# sce register map
Vendor: cramium
Cramium SoC, product name TBD
Registers are 32-bit, read-write, reset 0x0 unless marked. A register's access mark holds for its fields unless they carry their own. Offsets are from the block's base; lines under a group give offsets from that group; [hi:lo] are bit positions; {n}, {i} and the like mark numbered series; 'fields as' and 'values as' point back to an identical list; <NAME> marks a mode.

## Memory map
0x40028000 SCE_GLBSFR size 0x58
0x40029000 SCEDMA size 0x64
0x4002B000 COMBOHASH size 0x3C
0x4002C000 PKE size 0x44
0x4002D000 AES size 0x40
0x4002E000 TRNG size 0x4
0x4002F000 ALU size 0x4

## Further device data
memoryRegions:
  SCE baseAddress=0x40028000 size=0x00008000

## AES
Base 0x4002D000
0x00 SFR_CRFUNC
  [7:0] sfr_crfunc — sfr_crfunc read/write control register
0x04 SFR_AR
  [31:0] sfr_ar — sfr_ar performs action on write of value: 0x5a
0x08 SFR_SRMFSM
  [7:0] sfr_srmfsm — sfr_srmfsm read only status register
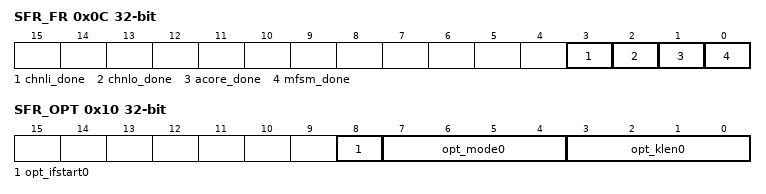
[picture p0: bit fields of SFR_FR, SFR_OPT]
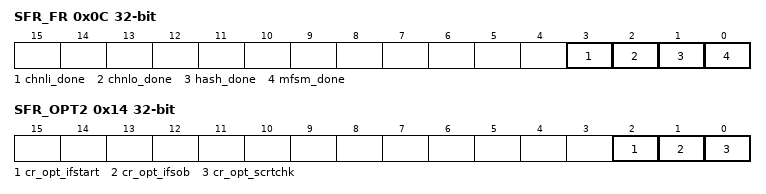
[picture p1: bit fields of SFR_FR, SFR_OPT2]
0x0C SFR_FR
  [3] chnli_done — sfr_srmfsm flag register. `1` means event happened, write back `1` in respective bit position to clear the flag
  [2] chnlo_done — sfr_srmfsm flag register. `1` means event happened, write back `1` in respective bit position to clear the flag
  [1] acore_done — sfr_srmfsm flag register. `1` means event happened, write back `1` in respective bit position to clear the flag
  [0] mfsm_done — sfr_srmfsm flag register. `1` means event happened, write back `1` in respective bit position to clear the flag
0x10 SFR_OPT
  [8] opt_ifstart0 — sfr_crfunc read/write control register
  [7:4] opt_mode0 — sfr_crfunc read/write control register
  [3:0] opt_klen0 — sfr_crfunc read/write control register
0x14 SFR_OPT1
  [15:0] sfr_opt1 — sfr_opt1 read/write control register
0x30 SFR_SEGPTR_PTRID_IV
  [11:0] PTRID_IV — cr_segptrstart read/write control register
0x34 SFR_SEGPTR_PTRID_AKEY
  [11:0] PTRID_AKEY — cr_segptrstart read/write control register
0x38 SFR_SEGPTR_PTRID_AIB
  [11:0] PTRID_AIB — cr_segptrstart read/write control register
0x3C SFR_SEGPTR_PTRID_AOB
  [11:0] PTRID_AOB — cr_segptrstart read/write control register

## COMBOHASH
Base 0x4002B000
0x00 SFR_CRFUNC
  [7:0] cr_func — cr_func read/write control register
0x04 SFR_AR
  [31:0] sfr_ar — sfr_ar performs action on write of value: 0x5a
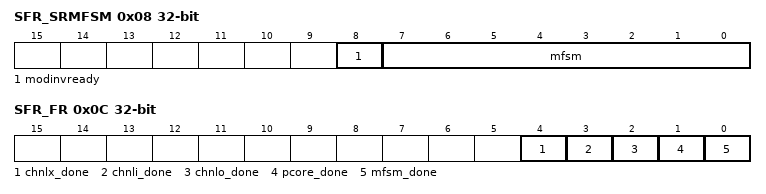
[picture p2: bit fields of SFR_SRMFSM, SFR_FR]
0x08 SFR_SRMFSM
  [7:0] mfsm — mfsm read only status register
0x0C SFR_FR
  [3] chnli_done — mfsm flag register. `1` means event happened, write back `1` in respective bit position to clear the flag
  [2] chnlo_done — mfsm flag register. `1` means event happened, write back `1` in respective bit position to clear the flag
  [1] hash_done — mfsm flag register. `1` means event happened, write back `1` in respective bit position to clear the flag
  [0] mfsm_done — mfsm flag register. `1` means event happened, write back `1` in respective bit position to clear the flag
0x10 SFR_OPT1
  [15:0] cr_opt_hashcnt — cr_opt_hashcnt read/write control register
0x14 SFR_OPT2
  [2] cr_opt_ifstart — cr_opt_hashcnt read/write control register
  [1] cr_opt_ifsob — cr_opt_hashcnt read/write control register
  [0] cr_opt_scrtchk — cr_opt_hashcnt read/write control register
0x20 SFR_SEGPTR_SEGID_LKEY
  [11:0] SEGID_LKEY — cr_segptrstart read/write control register
0x24 SFR_SEGPTR_SEGID_KEY
  [11:0] SEGID_KEY — cr_segptrstart read/write control register
0x2C SFR_SEGPTR_SEGID_SCRT
  [11:0] SEGID_SCRT — cr_segptrstart read/write control register
0x30 SFR_SEGPTR_SEGID_MSG
  [11:0] SEGID_MSG — cr_segptrstart read/write control register
0x34 SFR_SEGPTR_SEGID_HOUT
  [11:0] SEGID_HOUT — cr_segptrstart read/write control register
0x38 SFR_SEGPTR_SEGID_SOB
  [11:0] SEGID_SOB — cr_segptrstart read/write control register

## PKE
Base 0x4002C000
0x00 SFR_CRFUNC
  [7:0] sfr_crfunc — sfr_crfunc read/write control register
0x04 SFR_AR
  [31:0] sfr_ar — sfr_ar performs action on write of value: 0x5a
0x08 SFR_SRMFSM
  [8] modinvready — cr_segptrstart read only status register
  [7:0] mfsm — cr_segptrstart read only status register
0x0C SFR_FR
  [4] chnlx_done — cr_segptrstart flag register. `1` means event happened, write back `1` in respective bit position to clear the flag
  [3] chnli_done — cr_segptrstart flag register. `1` means event happened, write back `1` in respective bit position to clear the flag
  [2] chnlo_done — cr_segptrstart flag register. `1` means event happened, write back `1` in respective bit position to clear the flag
  [1] pcore_done — cr_segptrstart flag register. `1` means event happened, write back `1` in respective bit position to clear the flag
  [0] mfsm_done — cr_segptrstart flag register. `1` means event happened, write back `1` in respective bit position to clear the flag
0x10 SFR_OPTNW
  [12:0] sfr_optnw — sfr_optnw read/write control register
0x14 SFR_OPTEW
  [12:0] sfr_optew — sfr_optew read/write control register
0x20 SFR_OPTMASK
  [15:0] sfr_optmask — sfr_optmask read/write control register
0x30 SFR_SEGPTR_PTRID_PCON
  [11:0] PTRID_PCON — cr_segptrstart read/write control register
0x34 SFR_SEGPTR_PTRID_PIB0
  [11:0] PTRID_PIB0 — cr_segptrstart read/write control register
0x38 SFR_SEGPTR_PTRID_PIB1
  [11:0] PTRID_PIB1 — cr_segptrstart read/write control register
0x3C SFR_SEGPTR_PTRID_PKB
  [11:0] PTRID_PKB — cr_segptrstart read/write control register
0x40 SFR_SEGPTR_PTRID_POB
  [11:0] PTRID_POB — cr_segptrstart read/write control register

## SCEDMA
Base 0x40029000
0x00 SFR_SCHSTART_AR
  [31:0] sfr_schstart_ar — sfr_schstart_ar performs action on write of value: 0xaa
0x10 SFR_XCH_FUNC
  [0] sfr_xch_func — sfr_xch_func read/write control register
0x14 SFR_XCH_OPT
  [7:0] sfr_xch_opt — sfr_xch_opt read/write control register
0x18 SFR_XCH_AXSTART
  [31:0] sfr_xch_axstart — sfr_xch_axstart read/write control register
0x1C SFR_XCH_SEGID
  [7:0] sfr_xch_segid — sfr_xch_segid read/write control register
0x20 SFR_XCH_SEGSTART
  [11:0] xchcr_segstart — xchcr_segstart read/write control register
0x24 SFR_XCH_TRANSIZE
  [29:0] xchcr_transize — xchcr_transize read/write control register
0x30 SFR_SCH_FUNC
  [0] sfr_sch_func — sfr_sch_func read/write control register
0x34 SFR_SCH_OPT
  [7:0] sfr_sch_opt — sfr_sch_opt read/write control register
0x38 SFR_SCH_AXSTART
  [31:0] sfr_sch_axstart — sfr_sch_axstart read/write control register
0x3C SFR_SCH_SEGID
  [7:0] sfr_sch_segid — sfr_sch_segid read/write control register
0x40 SFR_SCH_SEGSTART
  [11:0] schcr_segstart — schcr_segstart read/write control register
0x44 SFR_SCH_TRANSIZE
  [29:0] schcr_transize — schcr_transize read/write control register
0x50 SFR_ICH_OPT
  [3:0] sfr_ich_opt — sfr_ich_opt read/write control register
0x54 SFR_ICH_SEGID
  [15:0] sfr_ich_segid — sfr_ich_segid read/write control register
0x58 SFR_ICH_RPSTART
  [11:0] ichcr_rpstart — ichcr_rpstart read/write control register
0x5C SFR_ICH_WPSTART
  [11:0] ichcr_wpstart — ichcr_wpstart read/write control register
0x60 SFR_ICH_TRANSIZE
  [11:0] ichcr_transize — ichcr_transize read/write control register

## SCE_GLBSFR
Base 0x40028000
0x00 SFR_SCEMODE
  [1:0] cr_scemode — cr_scemode read/write control register
0x04 SFR_SUBEN
  [15:0] cr_suben — cr_suben read/write control register
0x08 SFR_AHBS
  [4:0] cr_ahbsopt — cr_ahbsopt read/write control register
0x10 SFR_SRBUSY
  [15:0] sr_busy — sr_busy read only status register
0x14 SFR_FRDONE
  [15:0] fr_done — fr_done flag register. `1` means event happened, write back `1` in respective bit position to clear the flag
0x18 SFR_FRERR
  [15:0] fr_err — fr_err flag register. `1` means event happened, write back `1` in respective bit position to clear the flag
0x1C SFR_ARCLR
  [31:0] ar_clrram — ar_clrram performs action on write of value: 0xa5
0x20 SFR_TICKCYC
  [7:0] sfr_tickcyc — sfr_tickcyc read/write control register
0x24 SFR_TICKCNT
  [31:0] sfr_tickcnt — sfr_tickcnt read only status register
0x30 SFR_FFEN
  [5:0] cr_ffen — cr_ffen read/write control register
0x34 SFR_FFCLR
  [31:0] ar_ffclr — ar_ffclr performs action on write of value: (32'hff00+i)
{0x40+4i} SFR_FFCNT_SR_FF{i} (i=0..5)
  [15:0] sr_ff{i} — sr_ff read only status register
